# ATSAM4LC8B register map
Vendor: Atmel Corporation; Series: SAM4L; File version: A
CPU: CM4 r0p1, little endian, MPU, no FPU, 4 interrupt priority bits
Registers are 32-bit, write-only, reset 0x0 unless marked. A register's access mark holds for its fields unless they carry their own. Offsets are from the block's base; [hi:lo] are bit positions; {n}, {i} and the like mark numbered series.

## PM — Power Manager
Base 0x400E0000; register names take the prefix PM_
0x00 MCCTRL rw — Main Clock Control
  [2:0] MCSEL — Main Clock Select
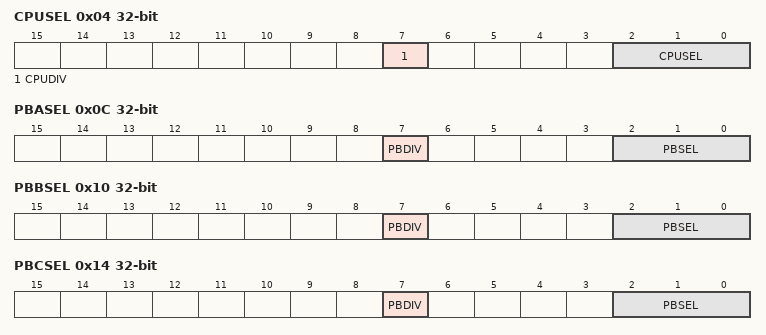
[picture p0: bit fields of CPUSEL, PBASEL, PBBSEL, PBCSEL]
0x04 CPUSEL rw — CPU Clock Select
  [7] CPUDIV — CPU Division
  [2:0] CPUSEL — CPU Clock Select
    0=fCPU:fmain. CPUDIV:; 1=fCPU:fmain / 2^(CPUSEL+1)
0x0C PBASEL rw — PBA Clock Select
  [7] PBDIV — PBA Division Select
  [2:0] PBSEL — PBA Clock Select
0x10 PBBSEL rw — PBB Clock Select
  [7] PBDIV — PBB Division Select
  [2:0] PBSEL — PBB Clock Select
0x14 PBCSEL rw — PBC Clock Select
  [7] PBDIV — PBC Division Select
  [2:0] PBSEL — PBC Clock Select
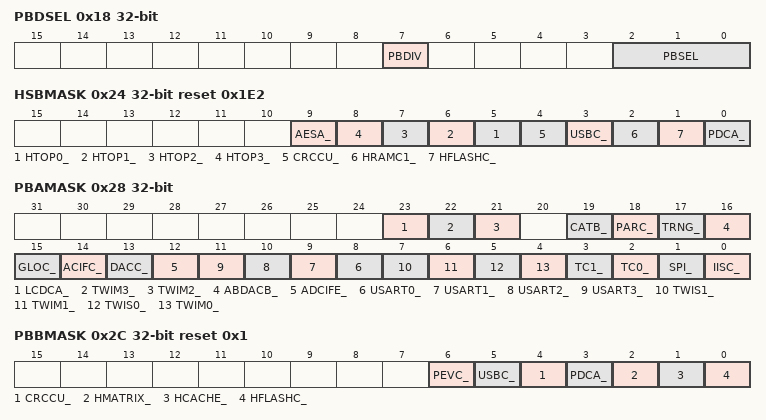
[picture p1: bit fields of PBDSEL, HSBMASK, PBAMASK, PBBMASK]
0x18 PBDSEL rw — PBD Clock Select
  [7] PBDIV — PBD Division Select
  [2:0] PBSEL — PBD Clock Select
0x20 CPUMASK rw reset 0x1
  [0] OCD_ — OCD CPU Clock Mask
0x24 HSBMASK rw reset 0x1E2
  [9] AESA_ — AESA HSB Clock Mask
  [n+5] HTOP{n}_ (n=0..3) — HTOP{n} HSB Clock Mask
  [4] CRCCU_ — CRCCU HSB Clock Mask
  [3] USBC_ — USBC HSB Clock Mask
  [2] HRAMC1_ — HRAMC1 HSB Clock Mask
  [1] HFLASHC_ — HFLASHC HSB Clock Mask
  [0] PDCA_ — PDCA HSB Clock Mask
0x28 PBAMASK rw
  [23] LCDCA_ — LCDCA APB Clock Enable
  [22] TWIM3_ — TWIM3 APB Clock Enable
  [21] TWIM2_ — TWIM2 APB Clock Enable
  [19] CATB_ — CATB APB Clock Enable
  [18] PARC_ — PARC APB Clock Enable
  [17] TRNG_ — TRNG APB Clock Enable
  [16] ABDACB_ — ABDACB APB Clock Enable
  [15] GLOC_ — GLOC APB Clock Enable
  [14] ACIFC_ — ACIFC APB Clock Enable
  [13] DACC_ — DACC APB Clock Enable
  [12] ADCIFE_ — ADCIFE APB Clock Enable
  [n+8] USART{n}_ (n=0..3) — USART{n} APB Clock Enable
  [7] TWIS1_ — TWIS1 APB Clock Enable
  [6] TWIM1_ — TWIM1 APB Clock Enable
  [5] TWIS0_ — TWIS0 APB Clock Enable
  [4] TWIM0_ — TWIM0 APB Clock Enable
  [3] TC1_ — TC1 APB Clock Enable
  [2] TC0_ — TC0 APB Clock Enable
  [1] SPI_ — SPI APB Clock Enable
  [0] IISC_ — IISC APB Clock Enable
0x2C PBBMASK rw reset 0x1
  [6] PEVC_ — PEVC APB Clock Enable
  [5] USBC_ — USBC APB Clock Enable
  [4] CRCCU_ — CRCCU APB Clock Enable
  [3] PDCA_ — PDCA APB Clock Enable
  [2] HMATRIX_ — HMATRIX APB Clock Enable
  [1] HCACHE_ — HCACHE APB Clock Enable
  [0] HFLASHC_ — HFLASHC APB Clock Enable
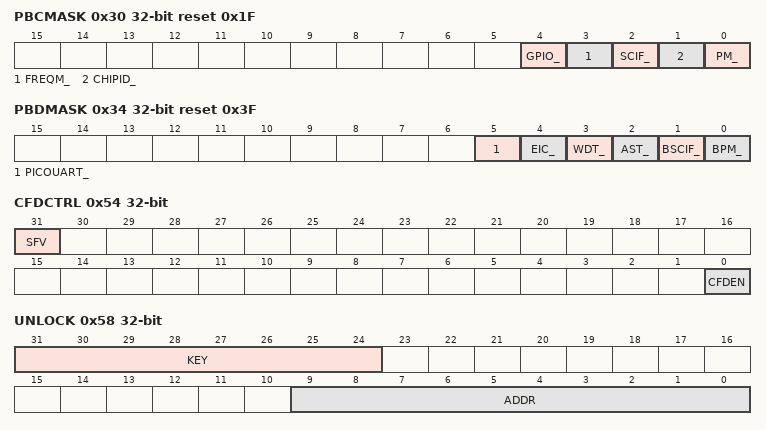
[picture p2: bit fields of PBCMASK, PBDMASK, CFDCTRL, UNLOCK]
0x30 PBCMASK rw reset 0x1F
  [4] GPIO_ — GPIO APB Clock Enable
  [3] FREQM_ — FREQM APB Clock Enable
  [2] SCIF_ — SCIF APB Clock Enable
  [1] CHIPID_ — CHIPID APB Clock Enable
  [0] PM_ — PM APB Clock Enable
0x34 PBDMASK rw reset 0x3F
  [5] PICOUART_ — PICOUART APB Clock Enable
  [4] EIC_ — EIC APB Clock Enable
  [3] WDT_ — WDT APB Clock Enable
  [2] AST_ — AST APB Clock Enable
  [1] BSCIF_ — BSCIF APB Clock Enable
  [0] BPM_ — BPM APB Clock Enable
0x40 PBADIVMASK rw — PBA Divided Clock Mask
0x54 CFDCTRL rw — Clock Failure Detector Control
  [31] SFV — Store Final Value
  [0] CFDEN — Clock Failure Detection Enable
0x58 UNLOCK
  [31:24] KEY — Unlock Key
  [9:0] ADDR — Unlock Address
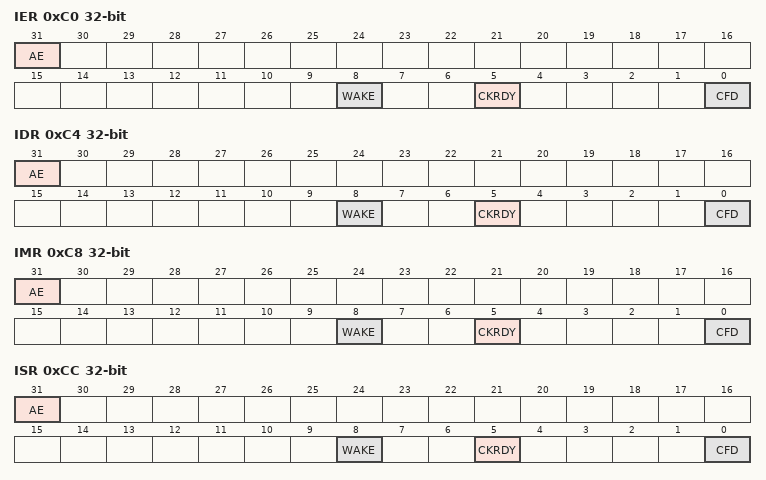
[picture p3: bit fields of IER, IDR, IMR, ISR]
0xC0 IER — Interrupt Enable Register
  [31] AE — Access Error Interrupt Enable
  [8] WAKE — Wake up Interrupt Enable
    0=No effect; 1=Disable Interrupt
  [5] CKRDY — Clock Ready Interrupt Enable
  [0] CFD — Clock Failure Detected Interrupt Enable
0xC4 IDR — Interrupt Disable Register
  [31] AE — Access Error Interrupt Disable
  [8] WAKE — Wake up Interrupt Disable
    0=No effect; 1=Disable Interrupt
  [5] CKRDY — Clock Ready Interrupt Disable
  [0] CFD — Clock Failure Detected Interrupt Disable
0xC8 IMR ro — Interrupt Mask Register
  [31] AE — Access Error Interrupt Mask
  [8] WAKE — Wake up Interrupt Mask
    0=No effect; 1=Disable Interrupt
  [5] CKRDY — Clock Ready Interrupt Mask
  [0] CFD — Clock Failure Detected Interrupt Mask
0xCC ISR ro — Interrupt Status Register
  [31] AE — Access Error Interrupt Status
  [8] WAKE — Wake up Interrupt Status
    0=No effect; 1=Disable Interrupt
  [5] CKRDY — Clock Ready Interrupt Status
  [0] CFD — Clock Failure Detected Interrupt Status
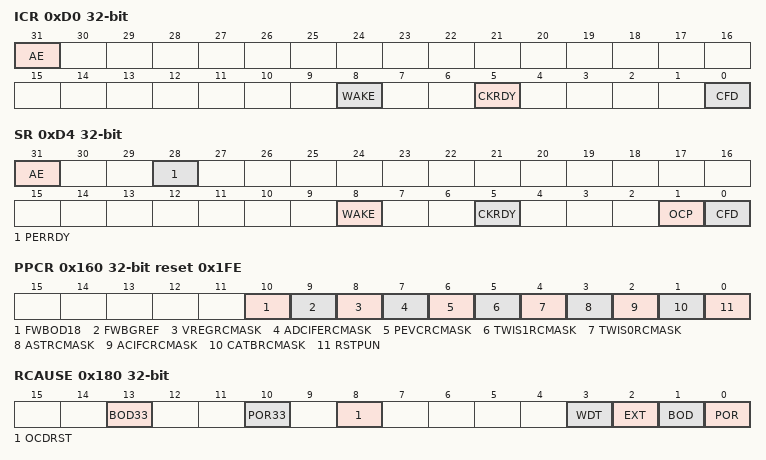
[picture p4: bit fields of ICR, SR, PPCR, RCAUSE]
0xD0 ICR — Interrupt Clear Register
  [31] AE — Access Error Interrupt Status Clear
  [8] WAKE — Wake up Interrupt Status Clear
  [5] CKRDY — Clock Ready Interrupt Status Clear
  [0] CFD — Clock Failure Detected Interrupt Status Clear
0xD4 SR ro — Status Register
  [31] AE — Access Error
  [28] PERRDY — Peripheral Ready
  [8] WAKE — Wake up
    0=No effect; 1=Disable Interrupt
  [5] CKRDY — Clock Ready
  [1] OCP — Over Clock Detected
  [0] CFD — Clock Failure Detected
0x160 PPCR rw reset 0x1FE — Peripheral Power Control Register
  [10] FWBOD18 — Flash Wait BOD18
  [9] FWBGREF — Flash Wait BGREF
  [8] VREGRCMASK — VREG Request Clock Mask
  [7] ADCIFERCMASK — ADCIFE Request Clock Mask
  [6] PEVCRCMASK — PEVC Request Clock Mask
  [5] TWIS1RCMASK — TWIS1 Request Clock Mask
  [4] TWIS0RCMASK — TWIS0 Request Clock Mask
  [3] ASTRCMASK — AST Request Clock Mask
  [2] ACIFCRCMASK — ACIFC Request Clock Mask
  [1] CATBRCMASK — CAT Request Clock Mask
  [0] RSTPUN — Reset Pullup
0x180 RCAUSE ro — Reset Cause Register
  [13] BOD33 — Brown-out 3.3V Reset
  [10] POR33 — Power-on Reset
  [8] OCDRST — OCD Reset
  [3] WDT — Watchdog Reset
  [2] EXT — External Reset Pin
  [1] BOD — Brown-out Reset
  [0] POR — Power-on Reset
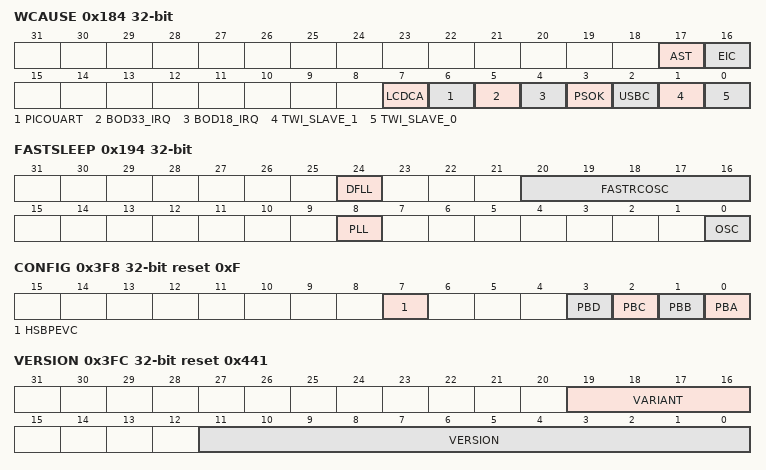
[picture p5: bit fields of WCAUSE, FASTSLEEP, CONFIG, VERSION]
0x184 WCAUSE ro — Wake Cause Register
  [17] AST — Asynchronous Timer
  [16] EIC — External Interrupt Controller
  [7] LCDCA — LCD Controller
  [6] PICOUART — Picopower UART
  [5] BOD33_IRQ — BOD33 Interrupt
  [4] BOD18_IRQ — BOD18 Interrupt
  [3] PSOK — Power Scaling OK
  [2] USBC — USB Device and Embedded Host Interface
  [1] TWI_SLAVE_1 — Two-wire Slave Interface 1
  [0] TWI_SLAVE_0 — Two-wire Slave Interface 0
0x188 AWEN rw — Asynchronous Wake Enable
  [31:0] AWEN — Asynchronous Wake Up
0x190 OBS rw — Obsvervability
0x194 FASTSLEEP rw
  [24] DFLL
  [20:16] FASTRCOSC — RC80 or FLO
  [8] PLL
  [0] OSC — Oscillator
0x3F8 CONFIG ro reset 0xF — Configuration Register
  [7] HSBPEVC — HSB PEVC Clock Implemented
  [3] PBD — APBD Implemented
  [2] PBC — APBC Implemented
  [1] PBB — APBB Implemented
  [0] PBA — APBA Implemented
0x3FC VERSION ro reset 0x441
  [19:16] VARIANT — Variant number
  [11:0] VERSION — Version number

## Notices in the file
Atmel Microcontroller Software Support
Copyright (c) 2014, Atmel Corporation
All rights reserved.
Redistribution and use in source and binary forms, with or without
modification, are permitted provided that the following condition is met:
- Redistributions of source code must retain the above copyright notice,
this list of conditions and the disclaimer below.
Atmel's name may not be used to endorse or promote products derived from
this software without specific prior written permission.
DISCLAIMER: THIS SOFTWARE IS PROVIDED BY ATMEL "AS IS" AND ANY EXPRESS OR
IMPLIED WARRANTIES, INCLUDING, BUT NOT LIMITED TO, THE IMPLIED WARRANTIES OF
MERCHANTABILITY, FITNESS FOR A PARTICULAR PURPOSE AND NON-INFRINGEMENT ARE
DISCLAIMED. IN NO EVENT SHALL ATMEL BE LIABLE FOR ANY DIRECT, INDIRECT,
INCIDENTAL, SPECIAL, EXEMPLARY, OR CONSEQUENTIAL DAMAGES (INCLUDING, BUT NOT
LIMITED TO, PROCUREMENT OF SUBSTITUTE GOODS OR SERVICES; LOSS OF USE, DATA,
OR PROFITS; OR BUSINESS INTERRUPTION) HOWEVER CAUSED AND ON ANY THEORY OF
LIABILITY, WHETHER IN CONTRACT, STRICT LIABILITY, OR TORT (INCLUDING
NEGLIGENCE OR OTHERWISE) ARISING IN ANY WAY OUT OF THE USE OF THIS SOFTWARE,
EVEN IF ADVISED OF THE POSSIBILITY OF SUCH DAMAGE.
